VERSION ""

NS_ :

BS_:

BU_:

BO_ 3221225472 VECTOR__INDEPENDENT_SIG_MSG: 0 Vector__XXX
 SG_ duty_select : 0|8@0+ (1,0) [0|255] "" Vector__XXX

BO_ 1169 AMI_DUTY: 1 Vector__XXX
 SG_ assi_status : 7|8@0+ (1,0) [0|255] "" Vector__XXX

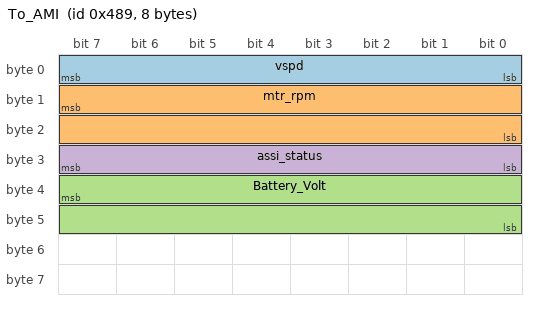
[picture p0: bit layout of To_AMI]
BO_ 1161 To_AMI: 8 Vector__XXX
 SG_ vspd : 7|8@0+ (1,0) [0|255] "m/s" Vector__XXX
 SG_ mtr_rpm : 15|16@0+ (1,0) [0|65535] "rpm" Vector__XXX
 SG_ Battery_Volt : 39|16@0+ (0.1,0) [0|6553.5] "V" Vector__XXX
 SG_ assi_status : 31|8@0+ (1,0) [0|255] "" Vector__XXX

CM_ BO_ 3221225472 "This is a message for not used signals, created by Vector CANdb++ DBC OLE DB Provider.";
